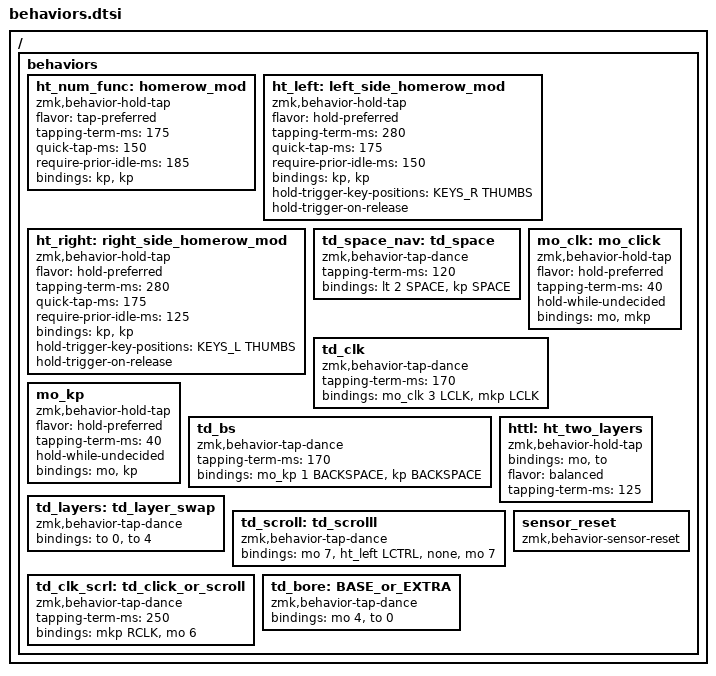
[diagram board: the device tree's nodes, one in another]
// Определение групп клавиш по их позициям в матрице
#define KEYS_L 0 1 2 3 4 5 12 13 14 15 16 17 24 25 26 27 28 29 36 37 38 19 20 21 22  // Левая рука
#define KEYS_R 6 7 8 9 10 11 18 19 20 21 22 23 30 31 32 33 34 35 39 40 16 15 14 13  // Правая рука
#define THUMBS 36 37 38 39 40  // Клавиши под большие пальцы

/*
──────────────────────────────────────────────────────────────
📘 ТАБЛИЦА ПОВЕДЕНИЙ
──────────────────────────────────────────────────────────────
│ Название       │ tap                         │ hold                        │ double-tap         │ Тип поведения │
├────────────────┼──────────────────────────────┼──────────────────────────────┼────────────────────┼────────────────┤
│ ht_num_func    │ обычное нажатие              │ модификатор/функция         │ —                  │ hold-tap       │
│ ht_left        │ символ                       │ модификатор (левая рука)    │ —                  │ hold-tap       │
│ ht_right       │ символ                       │ модификатор (правая рука)   │ —                  │ hold-tap       │
│ td_space_nav   │ пробел                       │ слой 2                      │ —                  │ tap-dance      │
│ mo_clk         │ клик мышью                   │ слой                        │ —                  │ hold-tap       │
│ td_clk         │ левый клик                   │ слой 3 + клик               │ —                  │ tap-dance      │
│ mo_kp          │ обычная клавиша              │ слой                        │ —                  │ hold-tap       │
│ td_bs          │ backspace                    │ слой 1                      │ —                  │ tap-dance      │
│ httl           │ переход на слой              │ временный слой              │ —                  │ hold-tap       │
│ td_layers      │ слой 0                       │ —                           │ слой 4             │ tap-dance      │
│ td_clk_scrl    │ правая кнопка мыши           │ слой 8 (scroll mode)        │ —                  │ tap-dance      │
│ td_bore        │ слой 4 (extras)      │ —                           │ слой 0 (base)      │ tap-dance      │
──────────────────────────────────────────────────────────────
*/

/ {
    behaviors {

        // Homerow-mod базовый (основа для модификаторов)
        ht_num_func: homerow_mod {
            compatible = "zmk,behavior-hold-tap";
            #binding-cells = <2>;
            flavor = "tap-preferred"; // если нажато коротко — регистрируется tap
            tapping-term-ms = <175>;  // время в мс до срабатывания hold
            quick-tap-ms = <150>;     // повторный tap в это время — считается tap
            require-prior-idle-ms = <185>; // предотвращает конфликт с предыдущими нажатиями
            bindings = <&kp>, <&kp>;  // 1-й параметр = hold, 2-й = tap
        };

        // Левая сторона — homerow mod
        ht_left: left_side_homerow_mod {
            compatible = "zmk,behavior-hold-tap";
            #binding-cells = <2>;
            flavor = "hold-preferred";       // баланс между tap и hold
            tapping-term-ms = <280>;   // большее время — т.к. левая рука часто держит моды
            quick-tap-ms = <175>;
            require-prior-idle-ms = <150>;
            bindings = <&kp>, <&kp>;
            hold-trigger-key-positions = <KEYS_R THUMBS>; // срабатывает hold, если нажаты клавиши правой руки
            hold-trigger-on-release;   // hold активируется при отпускании клавиши
        };

        // Правая сторона — homerow mod
        ht_right: right_side_homerow_mod {
            compatible = "zmk,behavior-hold-tap";
            #binding-cells = <2>;
            flavor = "hold-preferred";
            tapping-term-ms = <280>;
            quick-tap-ms = <175>;
            require-prior-idle-ms = <125>;
            bindings = <&kp>, <&kp>;
            hold-trigger-key-positions = <KEYS_L THUMBS>; // зеркально левой руке
            hold-trigger-on-release;
        };

        // Tap Dance: пробел / навигация
        td_space_nav: td_space {
            compatible = "zmk,behavior-tap-dance";
            #binding-cells = <0>;
            tapping-term-ms = <120>;
            // при удержании — активирует слой 2, при коротком нажатии — пробел
            bindings = <&lt 2 SPACE>, <&kp SPACE>; // hold = &lt 2 (Layer Tap на слой 2), tap = SPACE
        };

        // Hold-tap: слой / клик
        mo_clk: mo_click {
            compatible = "zmk,behavior-hold-tap";
            #binding-cells = <2>;
            flavor = "hold-preferred"; // приоритет удержания
            tapping-term-ms = <40>;    // очень короткое время для точного срабатывания
            hold-while-undecided;      // держит состояние, пока не решит tap/hold
            bindings = <&mo>, <&mkp>;  // hold = переключает слой, tap = mouse key press
        };

        // Tap Dance: клик / слой
        td_clk: td_clk {
            compatible = "zmk,behavior-tap-dance";
            #binding-cells = <0>;
            tapping-term-ms = <170>;
            // hold = mo_clk (слой + клик), tap = просто левый клик
            bindings = <&mo_clk 3 LCLK>, <&mkp LCLK>;
        };

        // Hold-tap: слой / обычная клавиша
        mo_kp: mo_kp {
            compatible = "zmk,behavior-hold-tap";
            #binding-cells = <2>;
            flavor       = "hold-preferred";
            tapping-term-ms = <40>;
            hold-while-undecided;
            bindings = <&mo>, <&kp>;
        };

        // Tap Dance: backspace / слой
        td_bs: td_bs {
            compatible = "zmk,behavior-tap-dance";
            #binding-cells = <0>;
            tapping-term-ms = <170>;
            // hold = слой 1, tap = backspace
            bindings = <&mo_kp 1 BACKSPACE>, <&kp BACKSPACE>;
        };

        // Hold-tap: переход между слоями
        httl: ht_two_layers {
            compatible = "zmk,behavior-hold-tap";
            bindings = <&mo>, <&to>;
            #binding-cells = <2>;
            flavor = "balanced";
            tapping-term-ms = <125>;
        };

        // Tap Dance: переключение слоёв
        td_layers: td_layer_swap {
            compatible = "zmk,behavior-tap-dance";
            #binding-cells = <0>;
            // tap = слой 0, double tap = слой 4
            bindings = <&to 0>, <&to 4>;
        };

        // Tap Dance: переключение слоёв
        td_scroll: td_scrolll {
            compatible = "zmk,behavior-tap-dance";
            #binding-cells = <0>;
            // tap = слой 0, double tap = слой 4
            bindings = <&mo 7>, <&ht_left LCTRL &none &mo 7>;
        };

        // Tap Dance: клик или скролл
        td_clk_scrl: td_click_or_scroll {
            compatible = "zmk,behavior-tap-dance";
            #binding-cells = <0>;
            tapping-term-ms = <250>;
    // tap = правая кнопка мыши, double tap = слой 6 (scroll mode)
    bindings = <&mkp RCLK>, <&mo 6>;
        };

        // Tap Dance: базовый слой или extras
        td_bore: BASE_or_EXTRA {
            compatible = "zmk,behavior-tap-dance";
            #binding-cells = <0>;
            // tap = слой 4 (extras), double tap = слой 0 (base)
            bindings = <&mo 4>, <&to 0>;
        };

        // Сброс сенсора трекбола (PMW3610) — power-up reset + переконфигурация.
        // Вызывается комбо 23+35. Нужен, когда трекбол «ускоряется» из-за
        // накопленного состояния сенсора (расфокус). Реализация — в
        // vendor/pmw3610-driver/src/behavior_sensor_reset.c
        sensor_reset: sensor_reset {
            compatible = "zmk,behavior-sensor-reset";
            #binding-cells = <0>;
        };
    };
};
